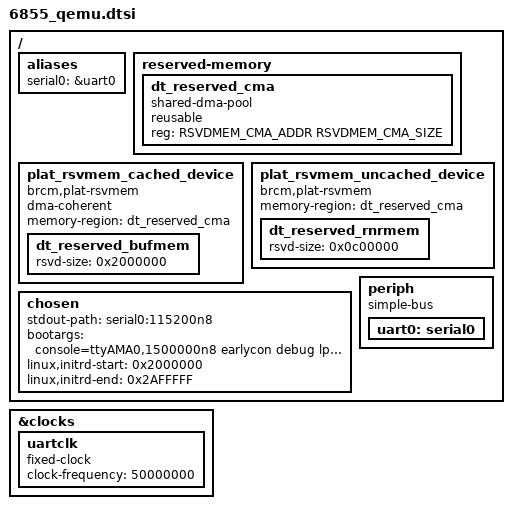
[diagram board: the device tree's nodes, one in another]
/dts-v1/;

#include "linux_autoconf.h"

#include <dt-bindings/interrupt-controller/arm-gic.h>
#include <dt-bindings/interrupt-controller/irq.h>

#define MODEL "Broadcom BCM96855"
#define COMPATIBLE "brcm,bcm96855"

/ {
	aliases {
		serial0		= &uart0;
	};

/* memory reservations */
#define CELLS_NUM 1
#define RSVDMEM_CMA_ADDR 0x07800000
#define RSVDMEM_CMA_SIZE 0x00800000

	reserved-memory {
        #address-cells = <CELLS_NUM>;
        #size-cells = <CELLS_NUM>;
        ranges;

        dt_reserved_cma: dt_reserved_cma {
            compatible = "shared-dma-pool";
            reusable;
            /* Bootloader will fill in the total size and offset */
            reg = <RSVDMEM_CMA_ADDR RSVDMEM_CMA_SIZE>;
        };
    };
    plat_rsvmem_cached_device {
        compatible = "brcm,plat-rsvmem";
        dma-coherent;
        memory-region = <&dt_reserved_cma>;

        dt_reserved_bufmem: dt_reserved_bufmem {
            rsvd-size = <0x2000000>;
        };
    };

    plat_rsvmem_uncached_device {
        compatible = "brcm,plat-rsvmem";
        memory-region = <&dt_reserved_cma>;
    
        dt_reserved_rnrmem: dt_reserved_rnrmem {
            rsvd-size = <0x0c00000>;
        };
    };	

	chosen {
		stdout-path = "serial0:115200n8";
        bootargs = "console=ttyAMA0,1500000n8 earlycon debug lpj=800000 ikosboot mem=128M,1048576 root=/dev/ram0 ro";
        linux,initrd-start = <0x2000000>;
		linux,initrd-end   = <0x2AFFFFF>;
    };

	/* clocks */
	#define PERIPH_CLK			200000000
	#define HS_SPI_PLL_CLK		200000000
	#include "../../ip/bcm_clocks.dtsi"

	periph {
		compatible = "simple-bus";
		#address-cells = <1>;
		#size-cells = <1>;
		ranges = <0x0 0xff800000 0x100000>;

		/* UART */
		uart0: serial0 {
			#define UART_OFFSET			0x12000
			#define UART_SIZE			0x1000
			#define UART_SPI			32
			#define UART_CLK_LABEL		refclk50mhz
			#define UART_CLK			50000000
			#include "../../ip/bcm_arm_uart.dtsi"
		};

	};
};

&clocks {
	#address-cells = <1>;
	#size-cells    = <1>;
	ranges;

	uartclk: uartclk {
		compatible			= "fixed-clock";
		#clock-cells		= <0>;
		clock-frequency		= <50000000>;
	};
};

